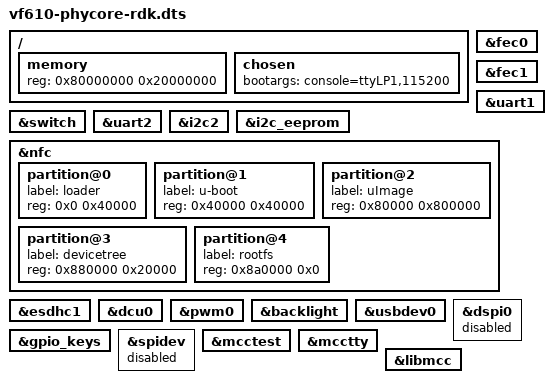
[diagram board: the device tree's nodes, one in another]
/*
 * Copyright (C) 2015 Anna Horstmann <ahorstmann@phytec.com> PHYTEC
 *
 * This program is free software; you can redistribute it and/or modify
 * it under the terms of the GNU General Public License version 2 as
 * published by the Free Software Foundation.
 */

/dts-v1/;
#include "vf610-phycore-som.dtsi"
#include "vf610-pcm-952.dtsi"

/ {
	memory {
		device_type = "memory";
		reg = <0x80000000 0x20000000>; /* 512 MB */
	};

	chosen {
		bootargs = "console=ttyLP1,115200";
	};
};


/* SoM */

&fec0 {
	status = "okay";
};

&fec1 {
	status = "okay";
};

&switch {
	status = "okay";
};

&uart1 {
	status = "okay";
};

&uart2 {
	status = "okay";
};

&i2c2 {
	status = "okay";
};

&i2c_eeprom {
	status = "okay";
};

&nfc {
	status = "okay";

	partition@0 {
		label = "loader";
		reg = <0x0 0x40000>;
	};

	partition@1 {
		label = "u-boot";
		reg = <0x40000 0x40000>;
	};

	partition@2 {
		label = "uImage";
		reg = <0x80000 0x800000>;
	};

	partition@3 {
		label = "devicetree";
		reg = <0x880000 0x20000>;
	};

	partition@4 {
		label = "rootfs";
		reg = <0x8a0000 0x0>;	/* size of zero, will extend to
					 * end of nand flash.
					 */
	};
};

/* Carrierboard */

&esdhc1 {
	status = "okay";
};

&dcu0 {
	status = "okay";
};

&pwm0 {
	status = "okay";
};

&backlight {
	status = "okay";
};

&usbdev0 {
	status = "okay";
};

&gpio_keys {
	status = "okay";
};

&dspi0 {
	status = "disabled";
};

&spidev {
	status = "disabled";
};

&mcctest{
       status = "okay";
};

&mcctty{
       status = "okay";
};

&libmcc{
       status = "okay";
};
